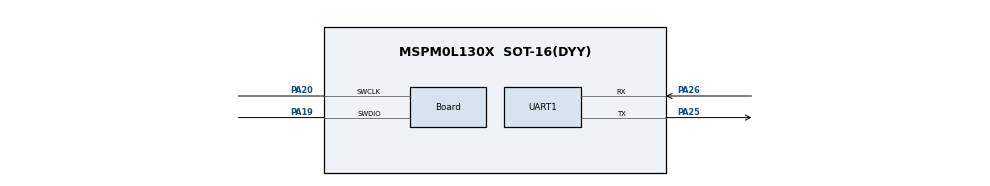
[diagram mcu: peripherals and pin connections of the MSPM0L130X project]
/**
 * @cliArgs --device "MSPM0L130X" --part "Default" --package "SOT-16(DYY)" --product "mspm0_sdk@2.04.00.06"
 * @versions {"tool":"1.23.0+4000"}
 */

/**
 * Import the modules used in this configuration.
 */
const GPIO          = scripting.addModule("/ti/driverlib/GPIO", {}, false);
const GPIO1         = GPIO.addInstance();
const SYSCTL        = scripting.addModule("/ti/driverlib/SYSCTL");
const UART          = scripting.addModule("/ti/driverlib/UART", {}, false);
const UART1         = UART.addInstance();
const ProjectConfig = scripting.addModule("/ti/project_config/ProjectConfig");

/**
 * Write custom configuration values to the imported modules.
 */
GPIO1.$name                         = "LCD";
GPIO1.port                          = "PORTA";
GPIO1.associatedPins.create(6);
GPIO1.associatedPins[0].$name       = "RS";
GPIO1.associatedPins[0].direction   = "INPUT";
GPIO1.associatedPins[0].assignedPin = "6";
GPIO1.associatedPins[1].$name       = "DB4";
GPIO1.associatedPins[1].direction   = "INPUT";
GPIO1.associatedPins[1].assignedPin = "17";
GPIO1.associatedPins[2].$name       = "DB5";
GPIO1.associatedPins[2].direction   = "INPUT";
GPIO1.associatedPins[2].assignedPin = "22";
GPIO1.associatedPins[3].$name       = "DB6";
GPIO1.associatedPins[3].direction   = "INPUT";
GPIO1.associatedPins[3].assignedPin = "23";
GPIO1.associatedPins[4].$name       = "DB7";
GPIO1.associatedPins[4].direction   = "INPUT";
GPIO1.associatedPins[4].assignedPin = "24";
GPIO1.associatedPins[5].$name       = "E";
GPIO1.associatedPins[5].direction   = "INPUT";
GPIO1.associatedPins[5].assignedPin = "2";
GPIO1.associatedPins[5].polarity    = "RISE";
GPIO1.associatedPins[5].interruptEn = true;

const Board                       = scripting.addModule("/ti/driverlib/Board", {}, false);
Board.peripheral.$assign          = "DEBUGSS";
Board.peripheral.swclkPin.$assign = "PA20";
Board.peripheral.swdioPin.$assign = "PA19";

SYSCTL.peripheral.$assign = "SYSCTL";

UART1.$name                    = "UART_0";
UART1.targetBaudRate           = 115200;
UART1.peripheral.rxPin.$assign = "PA26";
UART1.peripheral.txPin.$assign = "PA25";
UART1.txPinConfig.$name        = "ti_driverlib_gpio_GPIOPinGeneric0";
UART1.rxPinConfig.$name        = "ti_driverlib_gpio_GPIOPinGeneric1";

ProjectConfig.migrationCondition = true;

/**
 * Pinmux solution for unlocked pins/peripherals. This ensures that minor changes to the automatic solver in a future
 * version of the tool will not impact the pinmux you originally saw.  These lines can be completely deleted in order to
 * re-solve from scratch.
 */
GPIO1.associatedPins[0].pin.$suggestSolution = "PA6";
GPIO1.associatedPins[1].pin.$suggestSolution = "PA17/OPA1.IN0-";
GPIO1.associatedPins[2].pin.$suggestSolution = "PA22";
GPIO1.associatedPins[3].pin.$suggestSolution = "PA23";
GPIO1.associatedPins[4].pin.$suggestSolution = "PA24/OPA0.IN0-";
GPIO1.associatedPins[5].pin.$suggestSolution = "PA2";
UART1.peripheral.$suggestSolution            = "UART0";
